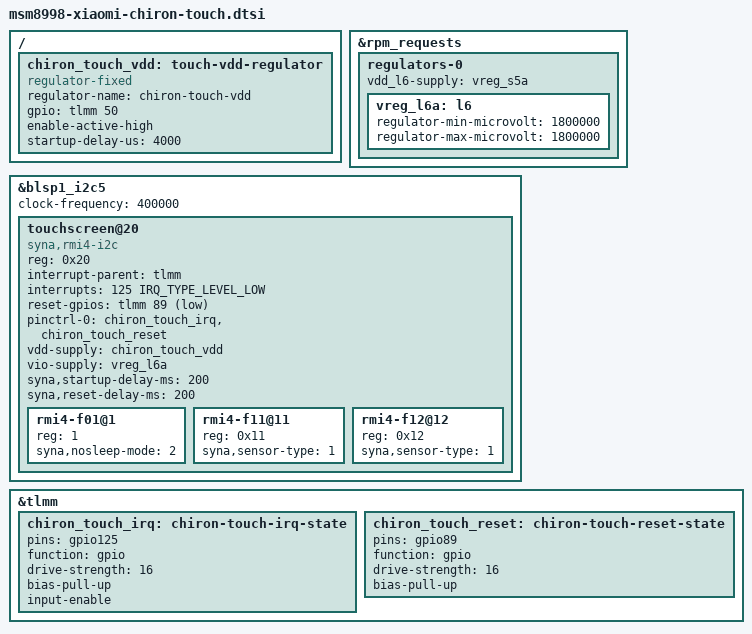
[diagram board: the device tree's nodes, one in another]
// SPDX-License-Identifier: BSD-3-Clause
/* Synaptics candidate; wiring checked against MIUI DTBs 00, 01 and 10. */
#include <dt-bindings/interrupt-controller/irq.h>

/ {
	chiron_touch_vdd: touch-vdd-regulator {
		compatible = "regulator-fixed";
		regulator-name = "chiron-touch-vdd";
		gpio = <&tlmm 50 GPIO_ACTIVE_HIGH>;
		enable-active-high;
		startup-delay-us = <4000>;
		/* Stock names an enable gate, without a programmable voltage. */
	};
};

&rpm_requests {
	regulators-0 {
		vdd_l6-supply = <&vreg_s5a>;
		vreg_l6a: l6 {
			regulator-min-microvolt = <1800000>;
			regulator-max-microvolt = <1800000>;
		};
	};
};

&blsp1_i2c5 {
	status = "okay";
	clock-frequency = <400000>;

	touchscreen@20 {
		compatible = "syna,rmi4-i2c";
		reg = <0x20>;
		#address-cells = <1>;
		#size-cells = <0>;
		interrupt-parent = <&tlmm>;
		interrupts = <125 IRQ_TYPE_LEVEL_LOW>;
		reset-gpios = <&tlmm 89 GPIO_ACTIVE_LOW>;
		pinctrl-names = "default";
		pinctrl-0 = <&chiron_touch_irq &chiron_touch_reset>;
		vdd-supply = <&chiron_touch_vdd>;
		vio-supply = <&vreg_l6a>;
		syna,startup-delay-ms = <200>;
		syna,reset-delay-ms = <200>;

		rmi4-f01@1 {
			reg = <1>;
			/* Keep active scanning responsive; RMI suspend still enters sleep. */
			syna,nosleep-mode = <2>;
		};
		rmi4-f11@11 {
			reg = <0x11>;
			syna,sensor-type = <1>;
		};
		rmi4-f12@12 {
			reg = <0x12>;
			syna,sensor-type = <1>;
		};
	};
};

&tlmm {
	chiron_touch_irq: chiron-touch-irq-state {
		pins = "gpio125";
		function = "gpio";
		drive-strength = <16>;
		bias-pull-up;
		input-enable;
	};
	chiron_touch_reset: chiron-touch-reset-state {
		pins = "gpio89";
		function = "gpio";
		drive-strength = <16>;
		bias-pull-up;
		/* The RMI I2C driver owns the output and reset sequence. */
	};
};
